VERSION ""

NS_ :

BS_:

BU_:

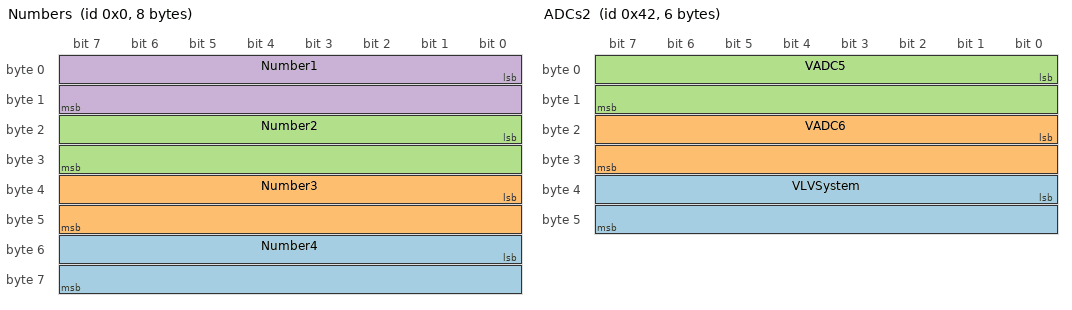
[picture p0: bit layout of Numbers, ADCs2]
BO_ 0 Numbers: 8 Vector__XXX
 SG_ Number4 : 48|16@1- (1,0) [-32768|32767] "" Vector__XXX
 SG_ Number3 : 32|16@1- (1,0) [-32768|32767] "" Vector__XXX
 SG_ Number2 : 16|16@1- (1,0) [-32768|32767] "" Vector__XXX
 SG_ Number1 : 0|16@1- (1,0) [-32768|32767] "" Vector__XXX

BO_ 66 ADCs2: 6 Vector__XXX
 SG_ VLVSystem : 32|16@1+ (0.00046327,0) [0|30.36039945] "" Vector__XXX
 SG_ VADC6 : 16|16@1+ (5.04E-05,0) [0|3.302964] "" Vector__XXX
 SG_ VADC5 : 0|16@1+ (5.04E-05,0) [0|3.302964] "" Vector__XXX

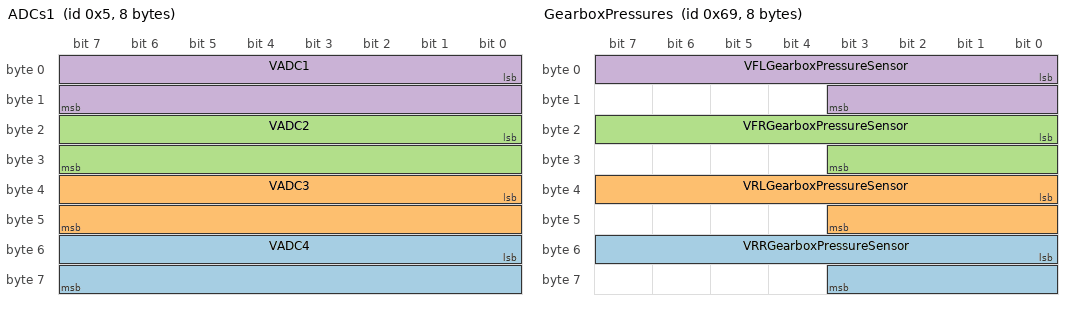
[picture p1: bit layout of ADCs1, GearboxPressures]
BO_ 5 ADCs1: 8 Vector__XXX
 SG_ VADC4 : 48|16@1+ (5.04E-05,0) [0|3.302964] "" Vector__XXX
 SG_ VADC3 : 32|16@1+ (5.04E-05,0) [0|3.302964] "" Vector__XXX
 SG_ VADC2 : 16|16@1+ (5.04E-05,0) [0|3.302964] "" Vector__XXX
 SG_ VADC1 : 0|16@1+ (5.04E-05,0) [0|3.302964] "" Vector__XXX

BO_ 105 GearboxPressures: 8 Vector__XXX
 SG_ VRRGearboxPressureSensor : 48|12@1+ (0.0012211,0) [0|5.0004045] "" Vector__XXX
 SG_ VRLGearboxPressureSensor : 32|12@1+ (0.0012211,0) [0|5.0004045] "" Vector__XXX
 SG_ VFRGearboxPressureSensor : 16|12@1+ (0.0012211,0) [0|5.0004045] "" Vector__XXX
 SG_ VFLGearboxPressureSensor : 0|12@1+ (0.0012211,0) [0|5.0004045] "" Vector__XXX

BA_DEF_  "BusType" STRING ;
BA_DEF_DEF_  "BusType" "CAN";
